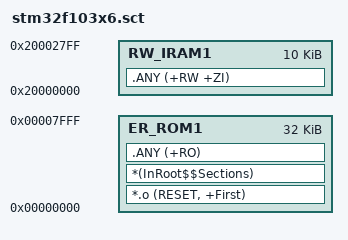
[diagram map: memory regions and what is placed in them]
; *************************************************************
; *** Scatter-Loading Description File for STM32F103x6      ***
; org LR_ROM1 0x08000000 0x00008000
; *************************************************************

LR_ROM1 0x0000000 0x00008000
 { ; load region size_region
   ER_ROM1 0x0000000 0x00008000
    { ; load address = execution address
      *.o (RESET, +First)
      *(InRoot$$Sections)
      .ANY (+RO)
    }
   RW_IRAM1 0x20000000 0x00002800
    { ; RW data
      .ANY (+RW +ZI)
    }
 }

